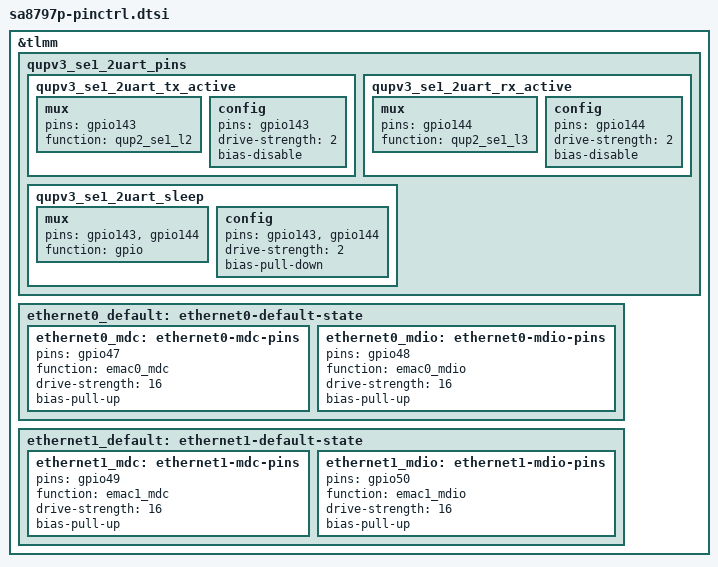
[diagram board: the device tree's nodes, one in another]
// SPDX-License-Identifier: BSD-3-Clause
/*
 * Copyright (c) 2025 Qualcomm Innovation Center, Inc. All rights reserved.
 */

&tlmm {
	qupv3_se1_2uart_pins: qupv3_se1_2uart_pins {
		qupv3_se1_2uart_tx_active: qupv3_se1_2uart_tx_active {
			mux {
				pins = "gpio143";
				function = "qup2_se1_l2";
			};

			config {
				pins = "gpio143";
				drive-strength = <2>;
				bias-disable;
			};
		};

		qupv3_se1_2uart_rx_active: qupv3_se1_2uart_rx_active {
			mux {
				pins = "gpio144";
				function = "qup2_se1_l3";
			};

			config {
				pins = "gpio144";
				drive-strength = <2>;
				bias-disable;
			};
		};

		qupv3_se1_2uart_sleep: qupv3_se1_2uart_sleep {
			mux {
				pins = "gpio143", "gpio144";
				function = "gpio";
			};

			config {
				pins = "gpio143", "gpio144";
				drive-strength = <2>;
				bias-pull-down;
			};
		};
	};

	ethernet0_default: ethernet0-default-state {
		ethernet0_mdc: ethernet0-mdc-pins {
			pins = "gpio47";
			function = "emac0_mdc";
			drive-strength = <16>;
			bias-pull-up;
		};

		ethernet0_mdio: ethernet0-mdio-pins {
			pins = "gpio48";
			function = "emac0_mdio";
			drive-strength = <16>;
			bias-pull-up;
		};
	};

	ethernet1_default: ethernet1-default-state {
		ethernet1_mdc: ethernet1-mdc-pins {
			pins = "gpio49";
			function = "emac1_mdc";
			drive-strength = <16>;
			bias-pull-up;
		};

		ethernet1_mdio: ethernet1-mdio-pins {
			pins = "gpio50";
			function = "emac1_mdio";
			drive-strength = <16>;
			bias-pull-up;
		};
	};
};

